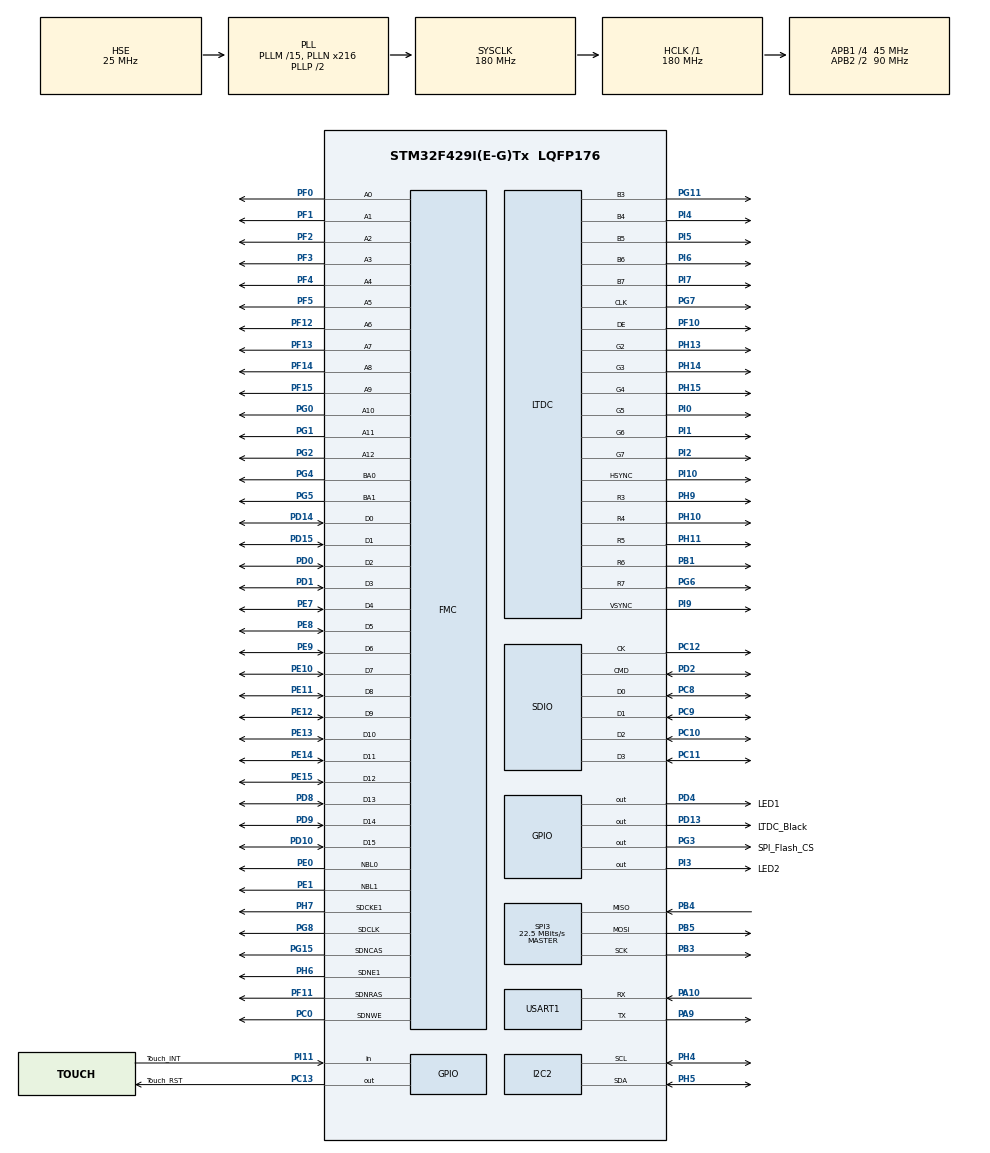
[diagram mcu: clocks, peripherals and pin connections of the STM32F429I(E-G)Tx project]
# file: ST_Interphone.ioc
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DMA2D.ColorMode=DMA2D_OUTPUT_RGB565
Dma.Request0=SDIO_RX
Dma.Request1=SDIO_TX
Dma.SDIO_RX.0.Direction=DMA_PERIPH_TO_MEMORY
Dma.SDIO_RX.0.FIFOMode=DMA_FIFOMODE_ENABLE
Dma.SDIO_RX.0.FIFOThreshold=DMA_FIFO_THRESHOLD_FULL
Dma.SDIO_RX.0.Instance=DMA2_Stream3
Dma.SDIO_RX.0.MemBurst=DMA_MBURST_INC4
Dma.SDIO_RX.0.MemDataAlignment=DMA_MDATAALIGN_WORD
Dma.SDIO_RX.0.MemInc=DMA_MINC_ENABLE
Dma.SDIO_RX.0.Mode=DMA_PFCTRL
Dma.SDIO_RX.0.PeriphBurst=DMA_PBURST_INC4
Dma.SDIO_RX.0.PeriphDataAlignment=DMA_PDATAALIGN_WORD
Dma.SDIO_RX.0.PeriphInc=DMA_PINC_DISABLE
Dma.SDIO_RX.0.Priority=DMA_PRIORITY_HIGH
Dma.SDIO_TX.1.Direction=DMA_MEMORY_TO_PERIPH
Dma.SDIO_TX.1.FIFOMode=DMA_FIFOMODE_ENABLE
Dma.SDIO_TX.1.FIFOThreshold=DMA_FIFO_THRESHOLD_FULL
Dma.SDIO_TX.1.Instance=DMA2_Stream6
Dma.SDIO_TX.1.MemBurst=DMA_MBURST_INC4
Dma.SDIO_TX.1.MemDataAlignment=DMA_MDATAALIGN_WORD
Dma.SDIO_TX.1.MemInc=DMA_MINC_ENABLE
Dma.SDIO_TX.1.Mode=DMA_PFCTRL
Dma.SDIO_TX.1.PeriphBurst=DMA_PBURST_INC4
Dma.SDIO_TX.1.PeriphDataAlignment=DMA_PDATAALIGN_WORD
Dma.SDIO_TX.1.PeriphInc=DMA_PINC_DISABLE
Dma.SDIO_TX.1.Priority=DMA_PRIORITY_HIGH
FATFS._CODE_PAGE=936
FATFS._USE_LABEL=1
FATFS._USE_LFN=2
FMC.CASLatency2=FMC_SDRAM_CAS_LATENCY_3
FMC.ColumnBitsNumber2=FMC_SDRAM_COLUMN_BITS_NUM_9
FMC.ExitSelfRefreshDelay2=7
FMC.LoadToActiveDelay2=2
FMC.RCDDelay2=2
FMC.RPDelay1=2
FMC.RPDelay2=2
FMC.ReadBurst1=FMC_SDRAM_RBURST_ENABLE
FMC.ReadBurst2=FMC_SDRAM_RBURST_ENABLE
FMC.ReadPipeDelay1=FMC_SDRAM_RPIPE_DELAY_1
FMC.ReadPipeDelay2=FMC_SDRAM_RPIPE_DELAY_1
FMC.RowCycleDelay1=7
FMC.RowCycleDelay2=7
FMC.SDClockPeriod1=FMC_SDRAM_CLOCK_PERIOD_2
FMC.SDClockPeriod2=FMC_SDRAM_CLOCK_PERIOD_2
FMC.SelfRefreshTime2=4
FMC.WriteRecoveryTime2=3
FREERTOS.Tasks01=defaultTask,24,128,StartDefaultTask,Default,NULL,Dynamic,NULL,NULL;Heartbeat_Led,8,128,Task_Heartbeat_Led,As weak,NULL,Dynamic,NULL,NULL;Peripheral_Init,8,1024,Task_Peripheral_Init,As weak,NULL,Dynamic,NULL,NULL;Task_LVGL,8,1024,Task_LVGL_Tick,As weak,NULL,Dynamic,NULL,NULL
I2C2.DutyCycle=I2C_DUTYCYCLE_2
I2C2.I2C_Mode=I2C_Fast
LTDC.ActiveW=800
LTDC.Alpha_L0=255
LTDC.Alpha_L1=255
LTDC.BlendingFactor1_L0=LTDC_BLENDING_FACTOR1_PAxCA
LTDC.BlendingFactor2_L0=LTDC_BLENDING_FACTOR2_PAxCA
LTDC.FBStartAdress_L0=0xD0000000
LTDC.FBStartAdress_L1=0xD0078000
LTDC.HBP=80
LTDC.HFP=200
LTDC.HSync=1
LTDC.ImageHeight_L0=480
LTDC.ImageHeight_L1=480
LTDC.ImageWidth_L0=800
LTDC.ImageWidth_L1=800
LTDC.Layers=0
LTDC.PixelFormat_L0=LTDC_PIXEL_FORMAT_RGB565
LTDC.VBP=40
LTDC.VFP=22
LTDC.VSync=1
LTDC.WindowX1_L0=800
LTDC.WindowX1_L1=800
LTDC.WindowY1_L0=480
LTDC.WindowY1_L1=480
Mcu.Family=STM32F4
Mcu.Name=STM32F429I(E-G)Tx
Mcu.Package=LQFP176
NVIC.DMA2_Stream3_IRQn=true\:5\:0\:false\:false\:true\:true\:false\:true\:true
NVIC.DMA2_Stream6_IRQn=true\:5\:0\:false\:false\:true\:true\:false\:true\:true
NVIC.PriorityGroup=NVIC_PRIORITYGROUP_4
NVIC.SDIO_IRQn=true\:5\:0\:false\:false\:true\:true\:true\:true\:true
NVIC.TIM6_DAC_IRQn=true\:15\:0\:false\:false\:true\:false\:false\:true\:true
NVIC.TIM7_IRQn=true\:5\:0\:true\:false\:true\:true\:true\:true\:true
NVIC.TimeBase=TIM6_DAC_IRQn
NVIC.TimeBaseIP=TIM6
PA10.Mode=Asynchronous
PA10.Signal=USART1_RX
PA13.Mode=Serial_Wire
PA13.Signal=SYS_JTMS-SWDIO
PA14.Mode=Serial_Wire
PA14.Signal=SYS_JTCK-SWCLK
PA9.Mode=Asynchronous
PA9.Signal=USART1_TX
PB1.GPIO_PuPd=GPIO_PULLUP
PB1.GPIO_Speed=GPIO_SPEED_FREQ_VERY_HIGH
PB1.Mode=RGB565
PB1.Signal=LTDC_R6
PB3.Mode=Full_Duplex_Master
PB3.Signal=SPI3_SCK
PB4.Mode=Full_Duplex_Master
PB4.Signal=SPI3_MISO
PB5.Mode=Full_Duplex_Master
PB5.Signal=SPI3_MOSI
PC0.Signal=FMC_SDNWE
PC10.Mode=SD_4_bits_Wide_bus
PC10.Signal=SDIO_D2
PC11.Mode=SD_4_bits_Wide_bus
PC11.Signal=SDIO_D3
PC12.GPIO_PuPd=GPIO_PULLUP
PC12.Mode=SD_4_bits_Wide_bus
PC12.Signal=SDIO_CK
PC13.GPIO_Label=Touch_RST
PC13.Signal=GPIO_Output
PC14/OSC32_IN.Mode=LSE-External-Oscillator
PC14/OSC32_IN.Signal=RCC_OSC32_IN
PC15/OSC32_OUT.Mode=LSE-External-Oscillator
PC15/OSC32_OUT.Signal=RCC_OSC32_OUT
PC8.GPIO_PuPd=GPIO_PULLUP
PC8.Mode=SD_4_bits_Wide_bus
PC8.Signal=SDIO_D0
PC9.Mode=SD_4_bits_Wide_bus
PC9.Signal=SDIO_D1
PD0.Signal=FMC_D2_DA2
PD1.Signal=FMC_D3_DA3
PD10.Signal=FMC_D15_DA15
PD13.GPIO_Label=LTDC_Black
PD13.GPIO_ModeDefaultOutputPP=GPIO_MODE_OUTPUT_PP
PD13.GPIO_PuPd=GPIO_PULLUP
PD13.PinState=GPIO_PIN_RESET
PD13.Signal=GPIO_Output
PD14.Signal=FMC_D0_DA0
PD15.Signal=FMC_D1_DA1
PD2.GPIO_PuPd=GPIO_PULLUP
PD2.Mode=SD_4_bits_Wide_bus
PD2.Signal=SDIO_CMD
PD4.GPIO_Label=LED1
PD4.PinState=GPIO_PIN_SET
PD4.Signal=GPIO_Output
PD8.Signal=FMC_D13_DA13
PD9.Signal=FMC_D14_DA14
PE0.Signal=FMC_NBL0
PE1.Signal=FMC_NBL1
PE10.Signal=FMC_D7_DA7
PE11.Signal=FMC_D8_DA8
PE12.Signal=FMC_D9_DA9
PE13.Signal=FMC_D10_DA10
PE14.Signal=FMC_D11_DA11
PE15.Signal=FMC_D12_DA12
PE7.Signal=FMC_D4_DA4
PE8.Signal=FMC_D5_DA5
PE9.Signal=FMC_D6_DA6
PF0.Signal=FMC_A0
PF1.Signal=FMC_A1
PF10.GPIO_PuPd=GPIO_PULLUP
PF10.GPIO_Speed=GPIO_SPEED_FREQ_VERY_HIGH
PF10.Mode=RGB565
PF10.Signal=LTDC_DE
PF11.Signal=FMC_SDNRAS
PF12.Signal=FMC_A6
PF13.Signal=FMC_A7
PF14.Signal=FMC_A8
PF15.Signal=FMC_A9
PF2.Signal=FMC_A2
PF3.Signal=FMC_A3
PF4.Signal=FMC_A4
PF5.Signal=FMC_A5
PG0.Signal=FMC_A10
PG1.Signal=FMC_A11
PG11.GPIO_PuPd=GPIO_PULLUP
PG11.GPIO_Speed=GPIO_SPEED_FREQ_VERY_HIGH
PG11.Mode=RGB565
PG11.Signal=LTDC_B3
PG15.Signal=FMC_SDNCAS
PG2.Signal=FMC_A12
PG3.GPIO_Label=SPI_Flash_CS
PG3.GPIO_PuPd=GPIO_NOPULL
PG3.GPIO_Speed=GPIO_SPEED_FREQ_VERY_HIGH
PG3.PinState=GPIO_PIN_SET
PG3.Signal=GPIO_Output
PG4.Signal=FMC_A14_BA0
PG5.Signal=FMC_A15_BA1
PG6.GPIO_PuPd=GPIO_PULLUP
PG6.GPIO_Speed=GPIO_SPEED_FREQ_VERY_HIGH
PG6.Mode=RGB565
PG6.Signal=LTDC_R7
PG7.GPIO_PuPd=GPIO_PULLUP
PG7.GPIO_Speed=GPIO_SPEED_FREQ_VERY_HIGH
PG7.Mode=RGB565
PG7.Signal=LTDC_CLK
PG8.Signal=FMC_SDCLK
PH0/OSC_IN.Mode=HSE-External-Oscillator
PH0/OSC_IN.Signal=RCC_OSC_IN
PH1/OSC_OUT.Mode=HSE-External-Oscillator
PH1/OSC_OUT.Signal=RCC_OSC_OUT
PH10.GPIO_PuPd=GPIO_PULLUP
PH10.GPIO_Speed=GPIO_SPEED_FREQ_VERY_HIGH
PH10.Mode=RGB565
PH10.Signal=LTDC_R4
PH11.GPIO_PuPd=GPIO_PULLUP
PH11.GPIO_Speed=GPIO_SPEED_FREQ_VERY_HIGH
PH11.Mode=RGB565
PH11.Signal=LTDC_R5
PH13.GPIO_PuPd=GPIO_PULLUP
PH13.GPIO_Speed=GPIO_SPEED_FREQ_VERY_HIGH
PH13.Mode=RGB565
PH13.Signal=LTDC_G2
PH14.GPIO_PuPd=GPIO_PULLUP
PH14.GPIO_Speed=GPIO_SPEED_FREQ_VERY_HIGH
PH14.Mode=RGB565
PH14.Signal=LTDC_G3
PH15.GPIO_PuPd=GPIO_PULLUP
PH15.GPIO_Speed=GPIO_SPEED_FREQ_VERY_HIGH
PH15.Mode=RGB565
PH15.Signal=LTDC_G4
PH4.Mode=I2C
PH4.Signal=I2C2_SCL
PH5.Mode=I2C
PH5.Signal=I2C2_SDA
PH6.Mode=SdramChipSelect2_2
PH6.Signal=FMC_SDNE1
PH7.Mode=SdramChipSelect2_2
PH7.Signal=FMC_SDCKE1
PH9.GPIO_PuPd=GPIO_PULLUP
PH9.GPIO_Speed=GPIO_SPEED_FREQ_VERY_HIGH
PH9.Mode=RGB565
PH9.Signal=LTDC_R3
PI0.GPIO_PuPd=GPIO_PULLUP
PI0.GPIO_Speed=GPIO_SPEED_FREQ_VERY_HIGH
PI0.Mode=RGB565
PI0.Signal=LTDC_G5
PI1.GPIO_PuPd=GPIO_PULLUP
PI1.GPIO_Speed=GPIO_SPEED_FREQ_VERY_HIGH
PI1.Mode=RGB565
PI1.Signal=LTDC_G6
PI10.GPIO_PuPd=GPIO_PULLUP
PI10.GPIO_Speed=GPIO_SPEED_FREQ_VERY_HIGH
PI10.Mode=RGB565
PI10.Signal=LTDC_HSYNC
PI11.GPIO_Label=Touch_INT
PI11.Signal=GPIO_Input
PI2.GPIO_PuPd=GPIO_PULLUP
PI2.GPIO_Speed=GPIO_SPEED_FREQ_VERY_HIGH
PI2.Mode=RGB565
PI2.Signal=LTDC_G7
PI3.GPIO_Label=LED2
PI3.PinState=GPIO_PIN_SET
PI3.Signal=GPIO_Output
PI4.GPIO_PuPd=GPIO_PULLUP
PI4.GPIO_Speed=GPIO_SPEED_FREQ_VERY_HIGH
PI4.Mode=RGB565
PI4.Signal=LTDC_B4
PI5.GPIO_PuPd=GPIO_PULLUP
PI5.GPIO_Speed=GPIO_SPEED_FREQ_VERY_HIGH
PI5.Mode=RGB565
PI5.Signal=LTDC_B5
PI6.GPIO_PuPd=GPIO_PULLUP
PI6.GPIO_Speed=GPIO_SPEED_FREQ_VERY_HIGH
PI6.Mode=RGB565
PI6.Signal=LTDC_B6
PI7.GPIO_PuPd=GPIO_PULLUP
PI7.GPIO_Speed=GPIO_SPEED_FREQ_VERY_HIGH
PI7.Mode=RGB565
PI7.Signal=LTDC_B7
PI9.GPIO_PuPd=GPIO_PULLUP
PI9.GPIO_Speed=GPIO_SPEED_FREQ_VERY_HIGH
PI9.Mode=RGB565
PI9.Signal=LTDC_VSYNC
ProjectManager.HeapSize=0xC000
ProjectManager.StackSize=0xC000
ProjectManager.TargetToolchain=MDK-ARM V5.32
RCC.48MHZClocksFreq_Value=45000000
RCC.AHBFreq_Value=180000000
RCC.APB1CLKDivider=RCC_HCLK_DIV4
RCC.APB1Freq_Value=45000000
RCC.APB1TimFreq_Value=90000000
RCC.APB2CLKDivider=RCC_HCLK_DIV2
RCC.APB2Freq_Value=90000000
RCC.APB2TimFreq_Value=180000000
RCC.CortexFreq_Value=180000000
RCC.HCLKFreq_Value=180000000
RCC.HSE_VALUE=25000000
RCC.HSI_VALUE=16000000
RCC.PLLM=15
RCC.PLLN=216
RCC.PLLQ=8
RCC.PLLSAIN=108
RCC.PLLSourceVirtual=RCC_PLLSOURCE_HSE
RCC.SYSCLKFreq_VALUE=180000000
RCC.SYSCLKSource=RCC_SYSCLKSOURCE_PLLCLK
RCC.VCOOutputFreq_Value=360000000
SDIO.ClockDiv=2
SH.FMC_A0.0=FMC_A0,13b-sda2
SH.FMC_A1.0=FMC_A1,13b-sda2
SH.FMC_A10.0=FMC_A10,13b-sda2
SH.FMC_A11.0=FMC_A11,13b-sda2
SH.FMC_A12.0=FMC_A12,13b-sda2
SH.FMC_A14_BA0.0=FMC_BA0,FourSdramBanks2
SH.FMC_A15_BA1.0=FMC_BA1,FourSdramBanks2
SH.FMC_A2.0=FMC_A2,13b-sda2
SH.FMC_A3.0=FMC_A3,13b-sda2
SH.FMC_A4.0=FMC_A4,13b-sda2
SH.FMC_A5.0=FMC_A5,13b-sda2
SH.FMC_A6.0=FMC_A6,13b-sda2
SH.FMC_A7.0=FMC_A7,13b-sda2
SH.FMC_A8.0=FMC_A8,13b-sda2
SH.FMC_A9.0=FMC_A9,13b-sda2
SH.FMC_D0_DA0.0=FMC_D0,sd-16b-d2
SH.FMC_D10_DA10.0=FMC_D10,sd-16b-d2
SH.FMC_D11_DA11.0=FMC_D11,sd-16b-d2
SH.FMC_D12_DA12.0=FMC_D12,sd-16b-d2
SH.FMC_D13_DA13.0=FMC_D13,sd-16b-d2
SH.FMC_D14_DA14.0=FMC_D14,sd-16b-d2
SH.FMC_D15_DA15.0=FMC_D15,sd-16b-d2
SH.FMC_D1_DA1.0=FMC_D1,sd-16b-d2
SH.FMC_D2_DA2.0=FMC_D2,sd-16b-d2
SH.FMC_D3_DA3.0=FMC_D3,sd-16b-d2
SH.FMC_D4_DA4.0=FMC_D4,sd-16b-d2
SH.FMC_D5_DA5.0=FMC_D5,sd-16b-d2
SH.FMC_D6_DA6.0=FMC_D6,sd-16b-d2
SH.FMC_D7_DA7.0=FMC_D7,sd-16b-d2
SH.FMC_D8_DA8.0=FMC_D8,sd-16b-d2
SH.FMC_D9_DA9.0=FMC_D9,sd-16b-d2
SH.FMC_NBL0.0=FMC_NBL0,Sd2ByteEnable2
SH.FMC_NBL1.0=FMC_NBL1,Sd2ByteEnable2
SH.FMC_SDCLK.0=FMC_SDCLK,13b-sda2
SH.FMC_SDNCAS.0=FMC_SDNCAS,13b-sda2
SH.FMC_SDNRAS.0=FMC_SDNRAS,13b-sda2
SH.FMC_SDNWE.0=FMC_SDNWE,13b-sda2
SPI3.BaudRatePrescaler=SPI_BAUDRATEPRESCALER_2
SPI3.CLKPhase=SPI_PHASE_2EDGE
SPI3.CLKPolarity=SPI_POLARITY_HIGH
SPI3.CalculateBaudRate=22.5 MBits/s
SPI3.Direction=SPI_DIRECTION_2LINES
SPI3.Mode=SPI_MODE_MASTER
SPI3.VirtualType=VM_MASTER
TIM7.AutoReloadPreload=TIM_AUTORELOAD_PRELOAD_ENABLE
TIM7.Period=1000-1
TIM7.Prescaler=90-1
USART1.VirtualMode=VM_ASYNC
VP_DMA2D_VS_DMA2D.Mode=DMA2D_Activate
VP_FATFS_VS_SDIO.Mode=SDIO
VP_FREERTOS_VS_CMSIS_V2.Mode=CMSIS_V2
VP_SYS_VS_tim6.Mode=TIM6
VP_TIM7_VS_ClockSourceINT.Mode=Enable_Timer
board=custom

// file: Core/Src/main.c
/* USER CODE BEGIN Header */
/**
  ******************************************************************************
  * @file           : main.c
  * @brief          : Main program body
  ******************************************************************************
  * @attention
  *
  * Copyright (c) 2025 STMicroelectronics.
  * All rights reserved.
  *
  * This software is licensed under terms that can be found in the LICENSE file
  * in the root directory of this software component.
  * If no LICENSE file comes with this software, it is provided AS-IS.
  *
  ******************************************************************************
  */
/* USER CODE END Header */
#include "main.h"
#include "cmsis_os.h"
#include "dma.h"
#include "dma2d.h"
#include "fatfs.h"
#include "i2c.h"
#include "ltdc.h"
#include "sdio.h"
#include "spi.h"
#include "tim.h"
#include "usart.h"
#include "gpio.h"
#include "fmc.h"

/* USER CODE BEGIN Includes */
#include "Com_Debug.h"
#include "App_SDRAM.h"
#include "Int_LCD.h"
#include "Int_Touch.h"
#include "Int_W25Q64.h"
#include "lv_demo_stress.h"

#include "lvgl.h"                // 它为整个LVGL提供了更完整的头文件引用
#include "lv_port_disp.h"        // LVGL的显示支持
#include "lv_port_indev.h"       // LVGL的触屏支持
/* USER CODE END Includes */

void SystemClock_Config(void);
void MX_FREERTOS_Init(void);

int main(void)
{

  /* MCU Configuration--------------------------------------------------------*/

  /* Reset of all peripherals, Initializes the Flash interface and the Systick. */
  HAL_Init();

  /* Configure the system clock */
  SystemClock_Config();

  /* Initialize all configured peripherals */
  MX_GPIO_Init();
  MX_DMA_Init();
  MX_USART1_UART_Init();
  MX_FMC_Init();
  MX_SDIO_SD_Init();
  MX_FATFS_Init();
  MX_LTDC_Init();
  MX_DMA2D_Init();
  MX_I2C2_Init();
  MX_SPI3_Init();
  MX_TIM7_Init();
  /* USER CODE BEGIN 2 */

//	SDRAM_Test();
    // 启动TIM7定时器
    HAL_TIM_Base_Start_IT(&htim7);

    // 初始化SDRAM内存管理器
    sdram_init();

	Touch_Init();
	lv_init();                             // LVGL 初始化
	lv_port_disp_init();                   // 注册LVGL的显示任务
	lv_port_indev_init();                  // 注册LVGL的触屏检测任务

    // 初始化W25Q64
    HAL_Delay(2000);
    W25Q64_Init();

  /* USER CODE END 2 */

  /* Init scheduler */
  osKernelInitialize();

  /* Call init function for freertos objects (in cmsis_os2.c) */
  MX_FREERTOS_Init();

  /* Start scheduler */
  osKernelStart();

  /* We should never get here as control is now taken by the scheduler */

  /* Infinite loop */
  while (1)
  {

  }
}

void SystemClock_Config(void)
{
  RCC_OscInitTypeDef RCC_OscInitStruct = {0};
  RCC_ClkInitTypeDef RCC_ClkInitStruct = {0};

  /** Configure the main internal regulator output voltage
  */
  __HAL_RCC_PWR_CLK_ENABLE();
  __HAL_PWR_VOLTAGESCALING_CONFIG(PWR_REGULATOR_VOLTAGE_SCALE1);

  /** Initializes the RCC Oscillators according to the specified parameters
  * in the RCC_OscInitTypeDef structure.
  */
  RCC_OscInitStruct.OscillatorType = RCC_OSCILLATORTYPE_HSE;
  RCC_OscInitStruct.HSEState = RCC_HSE_ON;
  RCC_OscInitStruct.PLL.PLLState = RCC_PLL_ON;
  RCC_OscInitStruct.PLL.PLLSource = RCC_PLLSOURCE_HSE;
  RCC_OscInitStruct.PLL.PLLM = 15;
  RCC_OscInitStruct.PLL.PLLN = 216;
  RCC_OscInitStruct.PLL.PLLP = RCC_PLLP_DIV2;
  RCC_OscInitStruct.PLL.PLLQ = 8;
  if (HAL_RCC_OscConfig(&RCC_OscInitStruct) != HAL_OK)
  {
    Error_Handler();
  }

  /** Activate the Over-Drive mode
  */
  if (HAL_PWREx_EnableOverDrive() != HAL_OK)
  {
    Error_Handler();
  }

  /** Initializes the CPU, AHB and APB buses clocks
  */
  RCC_ClkInitStruct.ClockType = RCC_CLOCKTYPE_HCLK|RCC_CLOCKTYPE_SYSCLK
                              |RCC_CLOCKTYPE_PCLK1|RCC_CLOCKTYPE_PCLK2;
  RCC_ClkInitStruct.SYSCLKSource = RCC_SYSCLKSOURCE_PLLCLK;
  RCC_ClkInitStruct.AHBCLKDivider = RCC_SYSCLK_DIV1;
  RCC_ClkInitStruct.APB1CLKDivider = RCC_HCLK_DIV4;
  RCC_ClkInitStruct.APB2CLKDivider = RCC_HCLK_DIV2;

  if (HAL_RCC_ClockConfig(&RCC_ClkInitStruct, FLASH_LATENCY_5) != HAL_OK)
  {
    Error_Handler();
  }
}

void HAL_TIM_PeriodElapsedCallback(TIM_HandleTypeDef *htim)
{
  if (htim->Instance == TIM6) {
    HAL_IncTick();
  }
  /* USER CODE BEGIN Callback 1 */
    if (htim->Instance == TIM7)
    {
		lv_tick_inc(1);
    }
  /* USER CODE END Callback 1 */
}

void Error_Handler(void)
{
  __disable_irq();
  while (1)
  {
  }
}

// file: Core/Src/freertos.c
/* USER CODE BEGIN Header */
/**
  ******************************************************************************
  * File Name          : freertos.c
  * Description        : Code for freertos applications
  ******************************************************************************
  * @attention
  *
  * Copyright (c) 2025 STMicroelectronics.
  * All rights reserved.
  *
  * This software is licensed under terms that can be found in the LICENSE file
  * in the root directory of this software component.
  * If no LICENSE file comes with this software, it is provided AS-IS.
  *
  ******************************************************************************
  */
/* USER CODE END Header */

#include "FreeRTOS.h"
#include "task.h"
#include "main.h"
#include "cmsis_os.h"

/* USER CODE BEGIN Includes */
TickType_t tick_count = 0;
/* USER CODE END Includes */

/* Definitions for defaultTask */
osThreadId_t defaultTaskHandle;
const osThreadAttr_t defaultTask_attributes = {
  .name = "defaultTask",
  .stack_size = 128 * 4,
  .priority = (osPriority_t) osPriorityNormal,
};
/* Definitions for Heartbeat_Led */
osThreadId_t Heartbeat_LedHandle;
const osThreadAttr_t Heartbeat_Led_attributes = {
  .name = "Heartbeat_Led",
  .stack_size = 128 * 4,
  .priority = (osPriority_t) osPriorityLow,
};
/* Definitions for Peripheral_Init */
osThreadId_t Peripheral_InitHandle;
const osThreadAttr_t Peripheral_Init_attributes = {
  .name = "Peripheral_Init",
  .stack_size = 1024 * 4,
  .priority = (osPriority_t) osPriorityLow,
};
/* Definitions for Task_LVGL */
osThreadId_t Task_LVGLHandle;
const osThreadAttr_t Task_LVGL_attributes = {
  .name = "Task_LVGL",
  .stack_size = 1024 * 4,
  .priority = (osPriority_t) osPriorityLow,
};

void StartDefaultTask(void *argument);
void Task_Heartbeat_Led(void *argument);
void Task_Peripheral_Init(void *argument);
void Task_LVGL_Tick(void *argument);

void MX_FREERTOS_Init(void); /* (MISRA C 2004 rule 8.1) */

void MX_FREERTOS_Init(void) {

  /* Create the thread(s) */
  /* creation of defaultTask */
  defaultTaskHandle = osThreadNew(StartDefaultTask, NULL, &defaultTask_attributes);

  /* creation of Heartbeat_Led */
  Heartbeat_LedHandle = osThreadNew(Task_Heartbeat_Led, NULL, &Heartbeat_Led_attributes);

  /* creation of Peripheral_Init */
  Peripheral_InitHandle = osThreadNew(Task_Peripheral_Init, NULL, &Peripheral_Init_attributes);

  /* creation of Task_LVGL */
  Task_LVGLHandle = osThreadNew(Task_LVGL_Tick, NULL, &Task_LVGL_attributes);

}

void StartDefaultTask(void *argument)
{
  /* USER CODE BEGIN StartDefaultTask */
  /* Infinite loop */
  for(;;)
  {
	  // ��ȡ����ӡϵͳtick����
	  tick_count = xTaskGetTickCount();
	  osDelay(1);
  }
  /* USER CODE END StartDefaultTask */
}

__weak void Task_Heartbeat_Led(void *argument)
{
  for(;;)
  {
    osDelay(1);
  }
}

__weak void Task_Peripheral_Init(void *argument)
{
  for(;;)
  {
    osDelay(1);
  }
}

__weak void Task_LVGL_Tick(void *argument)
{
  for(;;)
  {
    osDelay(1);
  }
}
